# HDSC_HC32F480 register map
Vendor: HDSC Co.Ltd; Series: ARMCM4; File version: 1.2
CPU: CM0 r0p0, little endian, no MPU, no FPU, 3 interrupt priority bits
Registers are 16-bit, read-write, reset 0x0 unless marked. A register's access mark holds for its fields unless they carry their own. Offsets are from the block's base; [hi:lo] are bit positions; {n}, {i} and the like mark numbered series.

## FCM
Base 0x40048400
0x00 LVR
0x04 UVR
0x08 CNTR ro
0x0C STR 32-bit
  [0] START
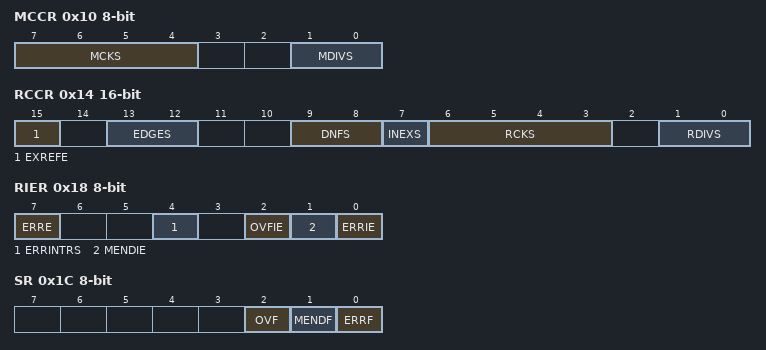
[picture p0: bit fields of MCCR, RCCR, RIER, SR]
0x10 MCCR 8-bit
  [7:4] MCKS, [1:0] MDIVS
0x14 RCCR
  [15] EXREFE, [13:12] EDGES, [9:8] DNFS, [7] INEXS, [6:3] RCKS, [1:0] RDIVS
0x18 RIER 8-bit
  [7] ERRE, [4] ERRINTRS, [2] OVFIE, [1] MENDIE, [0] ERRIE
0x1C SR 8-bit ro
  [2] OVF, [1] MENDF, [0] ERRF
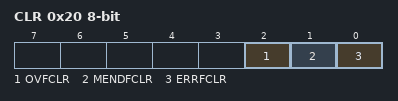
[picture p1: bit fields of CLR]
0x20 CLR 8-bit wo
  [2] OVFCLR, [1] MENDFCLR, [0] ERRFCLR

## HASH
Base 0x40008400
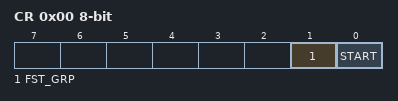
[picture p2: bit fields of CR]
0x00 CR 8-bit
  [1] FST_GRP, [0] START
0x10 HR7 32-bit
0x14 HR6 32-bit
0x18 HR5 32-bit
0x1C HR4 32-bit
0x20 HR3 32-bit
0x24 HR2 32-bit
0x28 HR1 32-bit
0x2C HR0 32-bit
0x40 DR15 32-bit
0x44 DR14 32-bit
0x48 DR13 32-bit
0x4C DR12 32-bit
0x50 DR11 32-bit
0x54 DR10 32-bit
0x58 DR9 32-bit
0x5C DR8 32-bit
0x60 DR7 32-bit
0x64 DR6 32-bit
0x68 DR5 32-bit
0x6C DR4 32-bit
0x70 DR3 32-bit
0x74 DR2 32-bit
0x78 DR1 32-bit
0x7C DR0 32-bit

## I2C
Base 0x4004B400
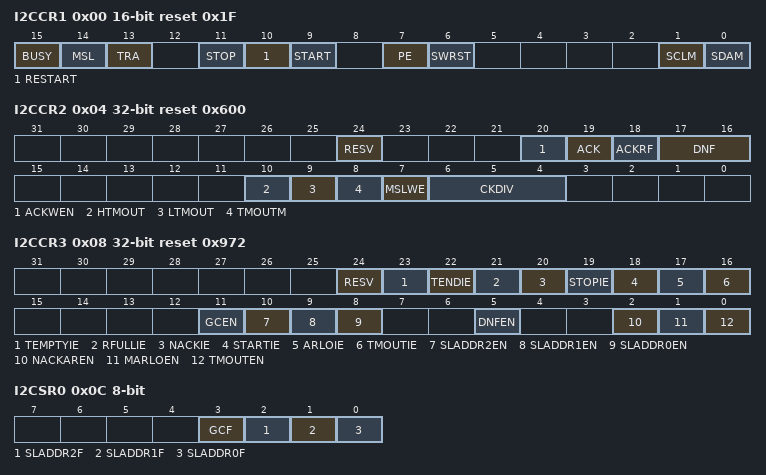
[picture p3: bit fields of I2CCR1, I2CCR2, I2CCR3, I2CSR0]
0x00 I2CCR1 ro reset 0x1F
  [15] BUSY, [14] MSL rw, [13] TRA rw, [11] STOP rw, [10] RESTART rw, [9] START rw, [7] PE rw, [6] SWRST rw, [1] SCLM, [0] SDAM
0x04 I2CCR2 32-bit reset 0x600
  [24] RESV, [20] ACKWEN, [19] ACK, [18] ACKRF ro, [17:16] DNF, [10] HTMOUT, [9] LTMOUT, [8] TMOUTM, [7] MSLWE, [6:4] CKDIV
0x08 I2CCR3 32-bit reset 0x972
  [24] RESV, [23] TEMPTYIE, [22] TENDIE, [21] RFULLIE, [20] NACKIE, [19] STOPIE, [18] STARTIE, [17] ARLOIE, [16] TMOUTIE, [11] GCEN, [10] SLADDR2EN, [9] SLADDR1EN, [8] SLADDR0EN, [5] DNFEN, [2] NACKAREN, [1] MARLOEN, [0] TMOUTEN
0x0C I2CSR0 8-bit
  [3] GCF, [2] SLADDR2F, [1] SLADDR1F, [0] SLADDR0F
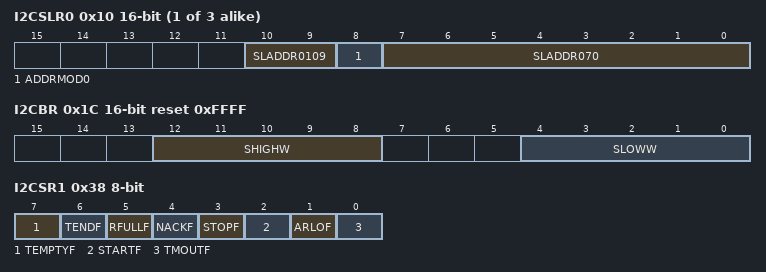
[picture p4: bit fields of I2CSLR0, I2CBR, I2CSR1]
{0x10+4i} I2CSLR{i} (i=0..2)
  [10:9] SLADDR{1000i+109:04}, [8] ADDRMOD{i}, [7:0] SLADDR{100i+70:03}
0x1C I2CBR reset 0xFFFF
  [12:8] SHIGHW, [4:0] SLOWW
0x20 I2CDTR 8-bit wo
0x24 I2CDRR 8-bit ro
0x38 I2CSR1 8-bit
  [7] TEMPTYF, [6] TENDF, [5] RFULLF, [4] NACKF, [3] STOPF, [2] STARTF, [1] ARLOF, [0] TMOUTF

## ICG
Base 0x00000400
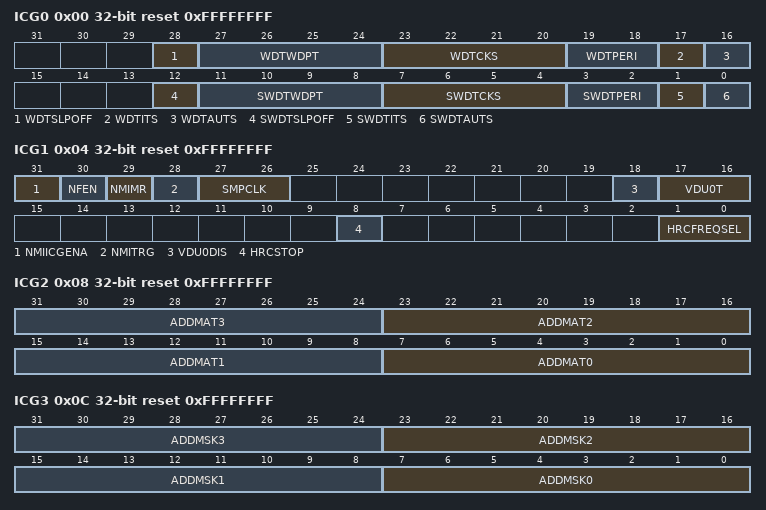
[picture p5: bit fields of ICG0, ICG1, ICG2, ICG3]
0x00 ICG0 32-bit ro reset 0xFFFFFFFF
  [28] WDTSLPOFF, [27:24] WDTWDPT, [23:20] WDTCKS, [19:18] WDTPERI, [17] WDTITS, [16] WDTAUTS, [12] SWDTSLPOFF, [11:8] SWDTWDPT, [7:4] SWDTCKS, [3:2] SWDTPERI, [1] SWDTITS, [0] SWDTAUTS
0x04 ICG1 32-bit ro reset 0xFFFFFFFF
  [31] NMIICGENA, [30] NFEN, [29] NMIMR, [28] NMITRG, [27:26] SMPCLK, [18] VDU0DIS, [17:16] VDU0T, [8] HRCSTOP, [1:0] HRCFREQSEL
0x08 ICG2 32-bit ro reset 0xFFFFFFFF
  [8n+7:8n] ADDMAT{n} (n=0..3)
0x0C ICG3 32-bit ro reset 0xFFFFFFFF
  [8n+7:8n] ADDMSK{n} (n=0..3)
{0x0+4i} ICG{i} 32-bit ro reset 0xFFFFFFFF (i=4..9)
0x28 ICGA 32-bit ro reset 0xFFFFFFFF
0x2C ICGB 32-bit ro reset 0xFFFFFFFF
0x30 ICGC 32-bit ro reset 0xFFFFFFFF
0x34 ICGD 32-bit ro reset 0xFFFFFFFF
0x38 ICGE 32-bit ro reset 0xFFFFFFFF
0x3C ICGF 32-bit ro reset 0xFFFFFFFF

## INTC
Base 0x40051000
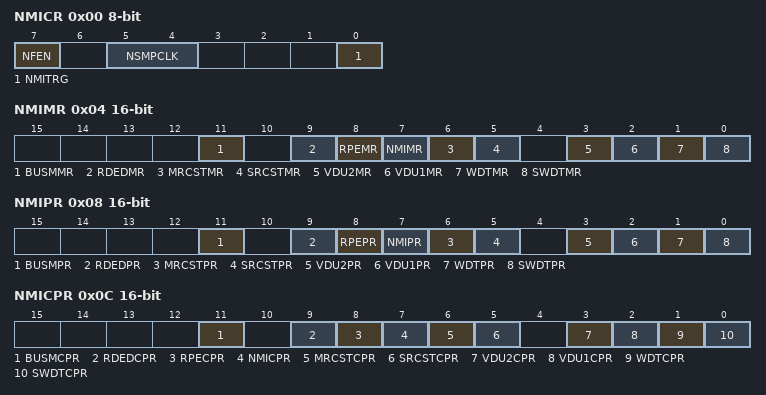
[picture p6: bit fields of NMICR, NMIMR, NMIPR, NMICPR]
0x00 NMICR 8-bit
  [7] NFEN, [5:4] NSMPCLK, [0] NMITRG
0x04 NMIMR
  [11] BUSMMR, [9] RDEDMR, [8] RPEMR, [7] NMIMR, [6] MRCSTMR, [5] SRCSTMR, [3] VDU2MR, [2] VDU1MR, [1] WDTMR, [0] SWDTMR
0x08 NMIPR
  [11] BUSMPR, [9] RDEDPR, [8] RPEPR, [7] NMIPR, [6] MRCSTPR, [5] SRCSTPR, [3] VDU2PR, [2] VDU1PR, [1] WDTPR, [0] SWDTPR
0x0C NMICPR
  [11] BUSMCPR, [9] RDEDCPR, [8] RPECPR, [7] NMICPR, [6] MRCSTCPR, [5] SRCSTCPR, [3] VDU2CPR, [2] VDU1CPR, [1] WDTCPR, [0] SWDTCPR
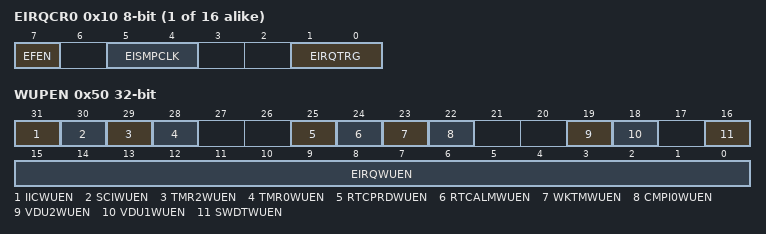
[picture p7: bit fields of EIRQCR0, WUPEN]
{0x10+4i} EIRQCR{i} 8-bit (i=0..15)
  [7] EFEN, [5:4] EISMPCLK, [1:0] EIRQTRG
0x50 WUPEN 32-bit
  [31] IICWUEN, [30] SCIWUEN, [29] TMR2WUEN, [28] TMR0WUEN, [25] RTCPRDWUEN, [24] RTCALMWUEN, [23] WKTMWUEN, [22] CMPI0WUEN, [19] VDU2WUEN, [18] VDU1WUEN, [16] SWDTWUEN, [15:0] EIRQWUEN
0x54 INTC_RESV0 32-bit
0x58 INTC_RESV1 32-bit
{0x5C+4i} INTSEL{i} (i=0..127)
  [8:0] INTSEL

## MSC0_I2C — desc MSC_I2C
Base 0x40021000
Same registers: MSC1_I2C 0x40021100, MSC2_I2C 0x40021200
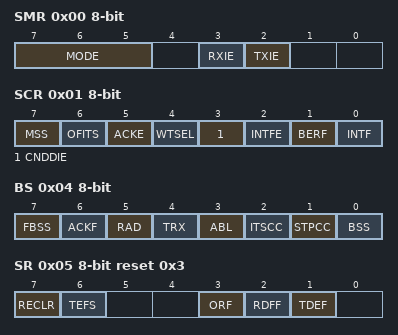
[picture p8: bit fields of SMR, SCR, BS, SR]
0x00 SMR 8-bit
  [7:5] MODE, [3] RXIE, [2] TXIE
0x01 SCR 8-bit
  [7] MSS, [6] OFITS, [5] ACKE, [4] WTSEL, [3] CNDDIE, [2] INTFE, [1] BERF, [0] INTF
0x04 BS 8-bit ro
  [7] FBSS, [6] ACKF, [5] RAD, [4] TRX, [3] ABL, [2] ITSCC rw, [1] STPCC rw, [0] BSS
0x05 SR 8-bit ro reset 0x3
  [7] RECLR rw, [6] TEFS rw, [3] ORF, [2] RDFF, [1] TDEF
0x08 TXDR_RXDR 8-bit
0x0C BRS
  [14:8] BRR1, [10:8] SA, [7] AE, [7:0] BRR0, [6:0] ADDR
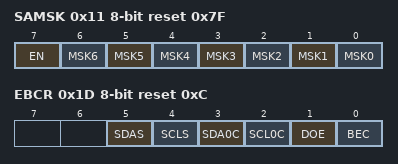
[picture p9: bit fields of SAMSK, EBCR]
0x11 SAMSK 8-bit reset 0x7F
  [7] EN, [n] MSK{n} (n=0..6)
0x1D EBCR 8-bit reset 0xC
  [5] SDAS ro, [4] SCLS ro, [3] SDA0C, [2] SCL0C, [1] DOE, [0] BEC
